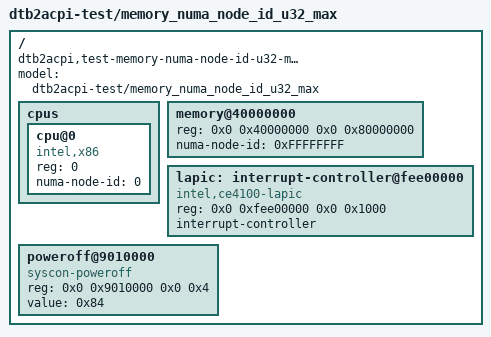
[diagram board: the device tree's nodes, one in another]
/dts-v1/;

/* `numa-node-id = <0xFFFFFFFF>` on a memory node collides with
 * `NUMA_TAG_NONE`. Rejected by `count_numa`'s memory walk as
 * `ValueOutOfRange { site: Memory, property: "numa-node-id" }`,
 * symmetric with the cpu-side guard.
 */

/ {
	#address-cells = <2>;
	#size-cells = <2>;
	model = "dtb2acpi-test/memory_numa_node_id_u32_max";
	compatible = "dtb2acpi,test-memory-numa-node-id-u32-max";

	cpus {
		#address-cells = <1>;
		#size-cells = <0>;

		cpu@0 {
			device_type = "cpu";
			reg = <0>;
			compatible = "intel,x86";
			numa-node-id = <0>;
		};
	};

	memory@40000000 {
		device_type = "memory";
		reg = <0x0 0x40000000 0x0 0x80000000>;
		numa-node-id = <0xFFFFFFFF>;
	};

		lapic: interrupt-controller@fee00000 {
		compatible = "intel,ce4100-lapic";
		reg = <0x0 0xfee00000 0x0 0x1000>;
		interrupt-controller;
		#interrupt-cells = <2>;
	};
		poweroff@9010000 {
		compatible = "syscon-poweroff";
		reg = <0x0 0x9010000 0x0 0x4>;
		value = <0x84>;
	};
};
